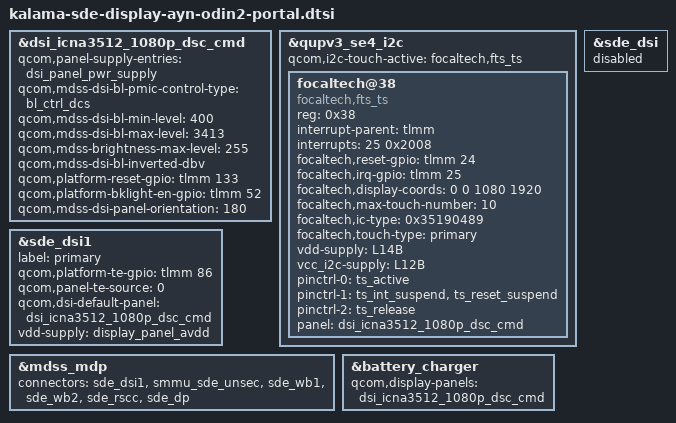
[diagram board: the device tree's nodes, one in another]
#include "kalama-sde-display-moorechip-common.dtsi"

&dsi_icna3512_1080p_dsc_cmd {
	qcom,panel-supply-entries = <&dsi_panel_pwr_supply>;
	qcom,mdss-dsi-bl-pmic-control-type = "bl_ctrl_dcs";
	qcom,mdss-dsi-bl-min-level = <400>;
	qcom,mdss-dsi-bl-max-level = <3413>;
	qcom,mdss-brightness-max-level = <255>;
	qcom,mdss-dsi-bl-inverted-dbv;
	qcom,platform-reset-gpio = <&tlmm 133 0>;
	qcom,platform-bklight-en-gpio = <&tlmm 52 0>;
	qcom,mdss-dsi-panel-orientation = "180";
};

&qupv3_se4_i2c {
	#address-cells = <1>;
	#size-cells = <0>;

	status = "okay";
	qcom,i2c-touch-active = "focaltech,fts_ts";

	focaltech@38 {
		compatible = "focaltech,fts_ts";
		reg = <0x38>;

		interrupt-parent = <&tlmm>;
		interrupts = <25 0x2008>;
		focaltech,reset-gpio = <&tlmm 24 0x0>;
		focaltech,irq-gpio = <&tlmm 25 0x02008>;
		focaltech,display-coords =  <0 0 1080 1920>;
		focaltech,max-touch-number = <10>;
		focaltech,ic-type = <0x35190489>;
		focaltech,touch-type = "primary";

		vdd-supply = <&L14B>;
		vcc_i2c-supply  = <&L12B>;

		pinctrl-names = "pmx_ts_active", "pmx_ts_suspend", "pmx_ts_release";
		pinctrl-0 = <&ts_active>;
		pinctrl-1 = <&ts_int_suspend &ts_reset_suspend>;
		pinctrl-2 = <&ts_release>;
		panel = <&dsi_icna3512_1080p_dsc_cmd>;
	};
};

&sde_dsi {
	status = "disabled";
};

&sde_dsi1 {
	label = "primary";

	qcom,platform-te-gpio = <&tlmm 86 0>;
	qcom,panel-te-source = <0>;

	qcom,dsi-default-panel = <&dsi_icna3512_1080p_dsc_cmd>;

	vdd-supply = <&display_panel_avdd>;
};

&mdss_mdp {
	connectors = <&sde_dsi1 &smmu_sde_unsec &sde_wb1 &sde_wb2 &sde_rscc &sde_dp>;
};

&battery_charger {
	qcom,display-panels = <&dsi_icna3512_1080p_dsc_cmd>;
};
